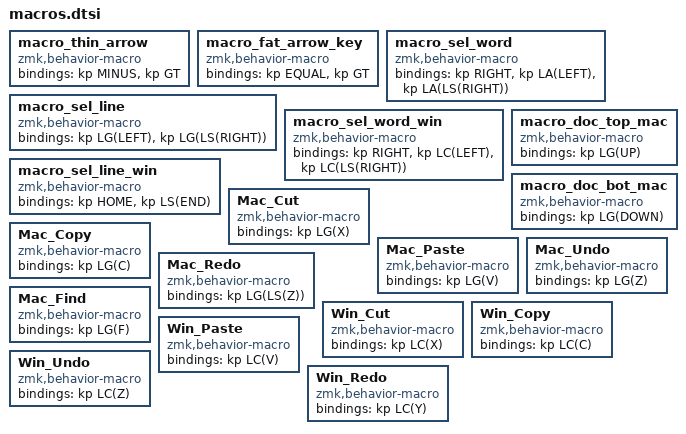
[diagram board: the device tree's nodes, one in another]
  /* ── Arrow digraph macros (used in SYM layer) ─────────────────────── */
  macro_thin_arrow: macro_thin_arrow {
    compatible = "zmk,behavior-macro";
    #binding-cells = <0>;
    bindings = <&kp MINUS>, <&kp GT>;
  };
  macro_fat_arrow_key: macro_fat_arrow_key {
    compatible = "zmk,behavior-macro";
    #binding-cells = <0>;
    bindings = <&kp EQUAL>, <&kp GT>;
  };

  /* ── Text editing macros (Mac) ─────────────────────────────────────── */
  macro_sel_word: macro_sel_word {
    compatible = "zmk,behavior-macro";
    #binding-cells = <0>;
    bindings = <&kp RIGHT>, <&kp LA(LEFT)>, <&kp LA(LS(RIGHT))>;
  };
  macro_sel_line: macro_sel_line {
    compatible = "zmk,behavior-macro";
    #binding-cells = <0>;
    bindings = <&kp LG(LEFT)>, <&kp LG(LS(RIGHT))>;
  };
  macro_sel_word_win: macro_sel_word_win {
    compatible = "zmk,behavior-macro";
    #binding-cells = <0>;
    bindings = <&kp RIGHT>, <&kp LC(LEFT)>, <&kp LC(LS(RIGHT))>;
  };
  macro_sel_line_win: macro_sel_line_win {
    compatible = "zmk,behavior-macro";
    #binding-cells = <0>;
    bindings = <&kp HOME>, <&kp LS(END)>;
  };

  /* ── Doc navigation (Mac) ──────────────────────────────────────────── */
  macro_doc_top_mac: macro_doc_top_mac {
    compatible = "zmk,behavior-macro";
    #binding-cells = <0>;
    bindings = <&kp LG(UP)>;
  };
  macro_doc_bot_mac: macro_doc_bot_mac {
    compatible = "zmk,behavior-macro";
    #binding-cells = <0>;
    bindings = <&kp LG(DOWN)>;
  };

  /* ── Mac shortcuts ─────────────────────────────────────────────────── */
  Mac_Cut: Mac_Cut {
    compatible = "zmk,behavior-macro";
    #binding-cells = <0>;
    bindings = <&kp LG(X)>;
  };
  Mac_Copy: Mac_Copy {
    compatible = "zmk,behavior-macro";
    #binding-cells = <0>;
    bindings = <&kp LG(C)>;
  };
  Mac_Paste: Mac_Paste {
    compatible = "zmk,behavior-macro";
    #binding-cells = <0>;
    bindings = <&kp LG(V)>;
  };
  Mac_Undo: Mac_Undo {
    compatible = "zmk,behavior-macro";
    #binding-cells = <0>;
    bindings = <&kp LG(Z)>;
  };
  Mac_Redo: Mac_Redo {
    compatible = "zmk,behavior-macro";
    #binding-cells = <0>;
    bindings = <&kp LG(LS(Z))>;
  };
  Mac_Find: Mac_Find {
    compatible = "zmk,behavior-macro";
    #binding-cells = <0>;
    bindings = <&kp LG(F)>;
  };

  /* ── Windows shortcuts ─────────────────────────────────────────────── */
  Win_Cut: Win_Cut {
    compatible = "zmk,behavior-macro";
    #binding-cells = <0>;
    bindings = <&kp LC(X)>;
  };
  Win_Copy: Win_Copy {
    compatible = "zmk,behavior-macro";
    #binding-cells = <0>;
    bindings = <&kp LC(C)>;
  };
  Win_Paste: Win_Paste {
    compatible = "zmk,behavior-macro";
    #binding-cells = <0>;
    bindings = <&kp LC(V)>;
  };
  Win_Undo: Win_Undo {
    compatible = "zmk,behavior-macro";
    #binding-cells = <0>;
    bindings = <&kp LC(Z)>;
  };
  Win_Redo: Win_Redo {
    compatible = "zmk,behavior-macro";
    #binding-cells = <0>;
    bindings = <&kp LC(Y)>;
  };
